AUTOSAR XML (schema 4.0)
standard types defined: float32, float64, sint16, sint32, sint8, uint16, uint32, uint8, void, boolean
package /ImplDataTypes
  7 x impl type, all with category=TYPE_REFERENCE, type-emitter=RTE:
    Impl_Height: implementation-data-type=uint8
    Impl_HeightBnState: implementation-data-type=Impl_MultiStateBtn
    Impl_Incline: implementation-data-type=uint8
    Impl_InclineBnState: implementation-data-type=Impl_MultiStateBtn
    Impl_MultiStateBtn: implementation-data-type=uint8
    Impl_Slide: implementation-data-type=uint8
    Impl_SlidetBnState: implementation-data-type=Impl_MultiStateBtn
package /MappingSets
  data type mapping set MappingSet
package /PortInterfaces/SenderReceiver
  sender receiver interface SrIf_SeatCtrlBtns
    data DE_HeightState: type=Impl_HeightBnState
    data DE_InclineState: type=Impl_InclineBnState
    data DE_SlideState: type=Impl_SlidetBnState
  sender receiver interface SrIf_SeatCtrlData
    data DE_Height: type=Impl_Height
    data DE_Incline: type=Impl_Incline
    data DE_Slide: type=Impl_Slide
package /SoftwareComponents
  swc implementation Impl_SWC_HMI: programming-language=C, sw-version=1.0.0, vendor-id=255, behavior=Ibhv_SWC_HMI
    code-descriptors:
      code Code: artifact-descriptors=autosar-engineering-object={short-label=SWC.c, category=SWSRC}
    resource consumption ResourceConsumption
  swc implementation Impl_SWC_SeatManger: programming-language=C, sw-version=1.0.0, vendor-id=255, behavior=Ibhv_SWC_SeatManger
    code-descriptors:
      code Code: artifact-descriptors=autosar-engineering-object={short-label=SWC.c, category=SWSRC}
    resource consumption ResourceConsumption
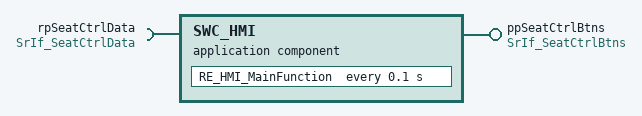
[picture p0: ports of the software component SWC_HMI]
  application sw component type SWC_HMI
    provide port ppSeatCtrlBtns: provided-interface=SrIf_SeatCtrlBtns
    require port rpSeatCtrlData: required-interface=SrIf_SeatCtrlData
    behavior Ibhv_SWC_HMI: data-type-mapping=MappingSet, handle-termination-and-restart=NO-SUPPORT
      timing event TE_RE_HMI_MainFunction_100ms: start-on-event=RE_HMI_MainFunction, period=0.1
      runnable RE_HMI_MainFunction
        data-receive-point-by-arguments:
          access DRP_rpSeatCtrlData_DE_Height: accessed-variable=rpSeatCtrlData.DE_Height
          access DRP_rpSeatCtrlData_DE_Incline: accessed-variable=rpSeatCtrlData.DE_Incline
          access DRP_rpSeatCtrlData_DE_Slide: accessed-variable=rpSeatCtrlData.DE_Slide
        data-send-points:
          access DSP_ppSeatCtrlBtns_DE_HeightState: accessed-variable=ppSeatCtrlBtns.DE_HeightState
          access DSP_ppSeatCtrlBtns_DE_InclineState: accessed-variable=ppSeatCtrlBtns.DE_InclineState
          access DSP_ppSeatCtrlBtns_DE_SlideState: accessed-variable=ppSeatCtrlBtns.DE_SlideState
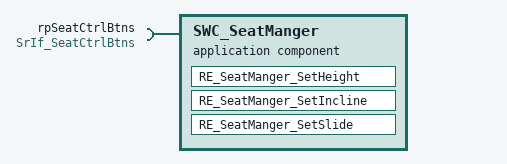
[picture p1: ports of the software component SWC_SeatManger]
  application sw component type SWC_SeatManger
    require port rpSeatCtrlBtns: required-interface=SrIf_SeatCtrlBtns
    behavior Ibhv_SWC_SeatManger: data-type-mapping=MappingSet, handle-termination-and-restart=NO-SUPPORT
      data received event DRE_rpSeatCtrlBtns_DE_HeightState: start-on-event=RE_SeatManger_SetHeight, data=rpSeatCtrlBtns.DE_HeightState
      data received event DRE_rpSeatCtrlBtns_DE_InclineState: start-on-event=RE_SeatManger_SetIncline, data=rpSeatCtrlBtns.DE_InclineState
      data received event DRE_rpSeatCtrlBtns_DE_SlideState: start-on-event=RE_SeatManger_SetSlide, data=rpSeatCtrlBtns.DE_SlideState
      runnable RE_SeatManger_SetHeight
        data-receive-point-by-arguments:
          access DRP_rpSeatCtrlBtns_DE_HeightState: accessed-variable=rpSeatCtrlBtns.DE_HeightState
      runnable RE_SeatManger_SetIncline
        data-receive-point-by-arguments:
          access DRP_rpSeatCtrlBtns_DE_InclineState: accessed-variable=rpSeatCtrlBtns.DE_InclineState
      runnable RE_SeatManger_SetSlide
        data-receive-point-by-arguments:
          access DRP_rpSeatCtrlBtns_DE_SlideState: accessed-variable=rpSeatCtrlBtns.DE_SlideState
package /Compositions
  composition sw component type Car_SeatComposition
    component SWC_HMI: type=SWC_HMI
    component SWC_SeatManger: type=SWC_SeatManger
    connect SWC_HMI.ppSeatCtrlBtns -> SWC_SeatManger.rpSeatCtrlBtns
